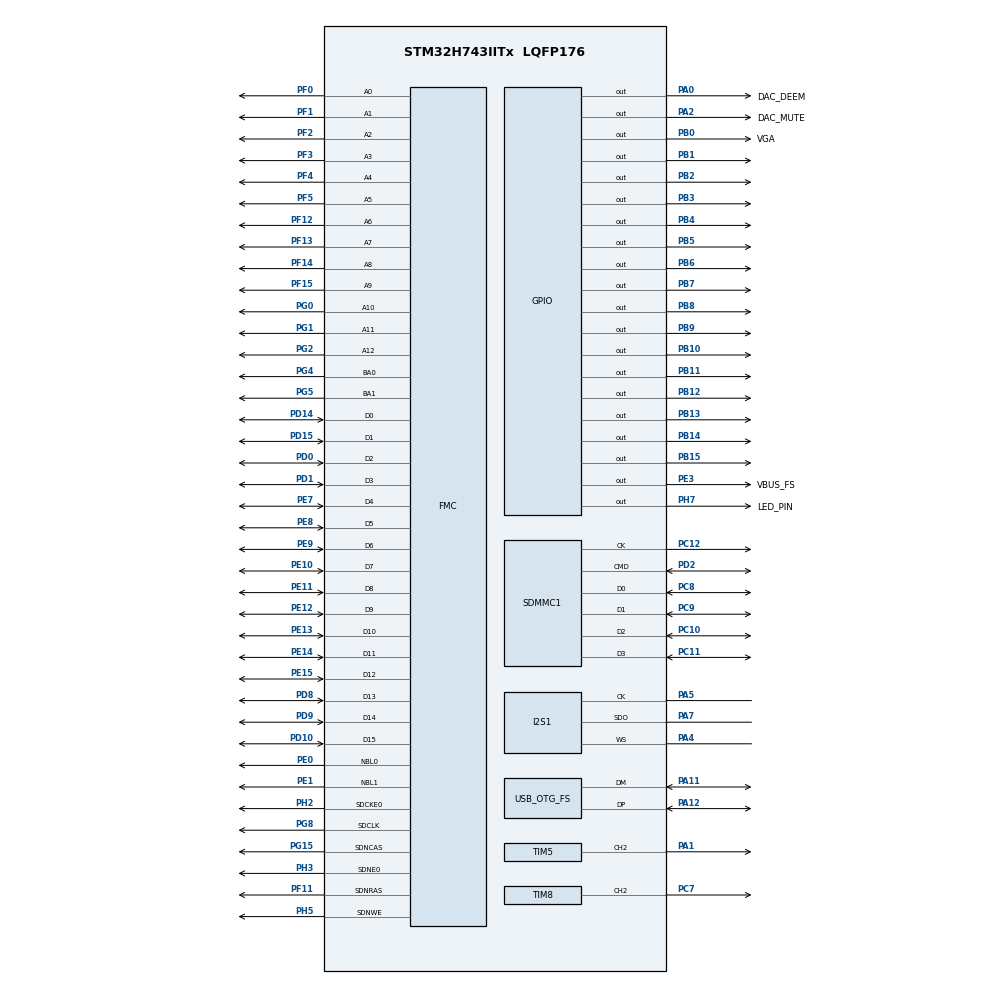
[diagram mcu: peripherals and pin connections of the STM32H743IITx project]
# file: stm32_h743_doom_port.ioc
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CORTEX_M7.AccessPermission_S-Cortex_Memory_Protection_Unit_Region1_Settings_S=MPU_REGION_PRIV_RO
CORTEX_M7.AccessPermission_S-Cortex_Memory_Protection_Unit_Region2_Settings_S=MPU_REGION_FULL_ACCESS
CORTEX_M7.AccessPermission_S-Cortex_Memory_Protection_Unit_Region3_Settings_S=MPU_REGION_FULL_ACCESS
CORTEX_M7.BaseAddress_S-Cortex_Memory_Protection_Unit_Region1_Settings_S=0x08000000
CORTEX_M7.BaseAddress_S-Cortex_Memory_Protection_Unit_Region2_Settings_S=0x38000000
CORTEX_M7.BaseAddress_S-Cortex_Memory_Protection_Unit_Region3_Settings_S=0xC0000000
CORTEX_M7.CPU_DCache=Disabled
CORTEX_M7.CPU_ICache=Enabled
CORTEX_M7.DisableExec_S-Cortex_Memory_Protection_Unit_Region2_Settings_S=MPU_INSTRUCTION_ACCESS_DISABLE
CORTEX_M7.DisableExec_S-Cortex_Memory_Protection_Unit_Region3_Settings_S=MPU_INSTRUCTION_ACCESS_DISABLE
CORTEX_M7.Enable_S-Cortex_Memory_Protection_Unit_Region1_Settings_S=MPU_REGION_ENABLE
CORTEX_M7.Enable_S-Cortex_Memory_Protection_Unit_Region2_Settings_S=MPU_REGION_ENABLE
CORTEX_M7.Enable_S-Cortex_Memory_Protection_Unit_Region3_Settings_S=MPU_REGION_ENABLE
CORTEX_M7.IsBufferable_S-Cortex_Memory_Protection_Unit_Region3_Settings_S=MPU_ACCESS_BUFFERABLE
CORTEX_M7.IsCacheable_S-Cortex_Memory_Protection_Unit_Region1_Settings_S=MPU_ACCESS_CACHEABLE
CORTEX_M7.IsCacheable_S-Cortex_Memory_Protection_Unit_Region3_Settings_S=MPU_ACCESS_CACHEABLE
CORTEX_M7.MPU_Control=__NULL
CORTEX_M7.Number_S-Cortex_Memory_Protection_Unit_Region2_Settings_S=MPU_REGION_NUMBER2
CORTEX_M7.Number_S-Cortex_Memory_Protection_Unit_Region3_Settings_S=MPU_REGION_NUMBER3
CORTEX_M7.Number_S-Cortex_Memory_Protection_Unit_Region4_Settings_S=MPU_REGION_NUMBER4
CORTEX_M7.Size_S-Cortex_Memory_Protection_Unit_Region1_Settings_S=MPU_REGION_SIZE_2MB
CORTEX_M7.Size_S-Cortex_Memory_Protection_Unit_Region2_Settings_S=MPU_REGION_SIZE_16MB
CORTEX_M7.Size_S-Cortex_Memory_Protection_Unit_Region3_Settings_S=MPU_REGION_SIZE_32MB
CORTEX_M7.SubRegionDisable_S-Cortex_Memory_Protection_Unit_Region2_Settings_S=0xEE
CORTEX_M7.TypeExtField_S-Cortex_Memory_Protection_Unit_Region2_Settings_S=MPU_TEX_LEVEL1
CORTEX_M7.TypeExtField_S-Cortex_Memory_Protection_Unit_Region3_Settings_S=MPU_TEX_LEVEL1
CORTEX_M7.default_mode_Activation=1
Dma.MEMTOMEM.1.Direction=DMA_MEMORY_TO_MEMORY
Dma.MEMTOMEM.1.EventEnable=DISABLE
Dma.MEMTOMEM.1.FIFOMode=DMA_FIFOMODE_ENABLE
Dma.MEMTOMEM.1.FIFOThreshold=DMA_FIFO_THRESHOLD_HALFFULL
Dma.MEMTOMEM.1.Instance=DMA1_Stream0
Dma.MEMTOMEM.1.MemBurst=DMA_MBURST_SINGLE
Dma.MEMTOMEM.1.MemDataAlignment=DMA_MDATAALIGN_WORD
Dma.MEMTOMEM.1.MemInc=DMA_MINC_ENABLE
Dma.MEMTOMEM.1.Mode=DMA_NORMAL
Dma.MEMTOMEM.1.PeriphBurst=DMA_PBURST_SINGLE
Dma.MEMTOMEM.1.PeriphDataAlignment=DMA_PDATAALIGN_WORD
Dma.MEMTOMEM.1.PeriphInc=DMA_PINC_ENABLE
Dma.MEMTOMEM.1.Polarity=HAL_DMAMUX_REQ_GEN_RISING
Dma.MEMTOMEM.1.Priority=DMA_PRIORITY_HIGH
Dma.MEMTOMEM.1.RequestNumber=1
Dma.MEMTOMEM.1.SignalID=NONE
Dma.MEMTOMEM.1.SyncEnable=DISABLE
Dma.MEMTOMEM.1.SyncPolarity=HAL_DMAMUX_SYNC_NO_EVENT
Dma.MEMTOMEM.1.SyncRequestNumber=1
Dma.MEMTOMEM.1.SyncSignalID=NONE
Dma.MEMTOMEM.3.Direction=DMA_MEMORY_TO_MEMORY
Dma.MEMTOMEM.3.EventEnable=DISABLE
Dma.MEMTOMEM.3.FIFOMode=DMA_FIFOMODE_ENABLE
Dma.MEMTOMEM.3.FIFOThreshold=DMA_FIFO_THRESHOLD_HALFFULL
Dma.MEMTOMEM.3.Instance=DMA1_Stream1
Dma.MEMTOMEM.3.MemBurst=DMA_MBURST_SINGLE
Dma.MEMTOMEM.3.MemDataAlignment=DMA_MDATAALIGN_WORD
Dma.MEMTOMEM.3.MemInc=DMA_MINC_ENABLE
Dma.MEMTOMEM.3.Mode=DMA_NORMAL
Dma.MEMTOMEM.3.PeriphBurst=DMA_PBURST_SINGLE
Dma.MEMTOMEM.3.PeriphDataAlignment=DMA_PDATAALIGN_WORD
Dma.MEMTOMEM.3.PeriphInc=DMA_PINC_DISABLE
Dma.MEMTOMEM.3.Polarity=HAL_DMAMUX_REQ_GEN_RISING
Dma.MEMTOMEM.3.Priority=DMA_PRIORITY_LOW
Dma.MEMTOMEM.3.RequestNumber=1
Dma.MEMTOMEM.3.SignalID=NONE
Dma.MEMTOMEM.3.SyncEnable=DISABLE
Dma.MEMTOMEM.3.SyncPolarity=HAL_DMAMUX_SYNC_NO_EVENT
Dma.MEMTOMEM.3.SyncRequestNumber=1
Dma.MEMTOMEM.3.SyncSignalID=NONE
Dma.Request0=TIM1_UP
Dma.Request1=MEMTOMEM
Dma.Request2=SPI1_TX
Dma.Request3=MEMTOMEM
Dma.SPI1_TX.2.Direction=DMA_MEMORY_TO_PERIPH
Dma.SPI1_TX.2.EventEnable=DISABLE
Dma.SPI1_TX.2.FIFOMode=DMA_FIFOMODE_ENABLE
Dma.SPI1_TX.2.FIFOThreshold=DMA_FIFO_THRESHOLD_FULL
Dma.SPI1_TX.2.Instance=DMA1_Stream2
Dma.SPI1_TX.2.MemBurst=DMA_MBURST_SINGLE
Dma.SPI1_TX.2.MemDataAlignment=DMA_MDATAALIGN_HALFWORD
Dma.SPI1_TX.2.MemInc=DMA_MINC_ENABLE
Dma.SPI1_TX.2.Mode=DMA_CIRCULAR
Dma.SPI1_TX.2.PeriphBurst=DMA_PBURST_SINGLE
Dma.SPI1_TX.2.PeriphDataAlignment=DMA_PDATAALIGN_HALFWORD
Dma.SPI1_TX.2.PeriphInc=DMA_PINC_DISABLE
Dma.SPI1_TX.2.Polarity=HAL_DMAMUX_REQ_GEN_RISING
Dma.SPI1_TX.2.Priority=DMA_PRIORITY_MEDIUM
Dma.SPI1_TX.2.RequestNumber=1
Dma.SPI1_TX.2.SignalID=NONE
Dma.SPI1_TX.2.SyncEnable=DISABLE
Dma.SPI1_TX.2.SyncPolarity=HAL_DMAMUX_SYNC_NO_EVENT
Dma.SPI1_TX.2.SyncRequestNumber=1
Dma.SPI1_TX.2.SyncSignalID=NONE
Dma.TIM1_UP.0.Direction=DMA_MEMORY_TO_PERIPH
Dma.TIM1_UP.0.EventEnable=DISABLE
Dma.TIM1_UP.0.FIFOMode=DMA_FIFOMODE_ENABLE
Dma.TIM1_UP.0.FIFOThreshold=DMA_FIFO_THRESHOLD_HALFFULL
Dma.TIM1_UP.0.Instance=DMA2_Stream0
Dma.TIM1_UP.0.MemBurst=DMA_MBURST_SINGLE
Dma.TIM1_UP.0.MemDataAlignment=DMA_MDATAALIGN_HALFWORD
Dma.TIM1_UP.0.MemInc=DMA_MINC_ENABLE
Dma.TIM1_UP.0.Mode=DMA_CIRCULAR
Dma.TIM1_UP.0.PeriphBurst=DMA_PBURST_SINGLE
Dma.TIM1_UP.0.PeriphDataAlignment=DMA_PDATAALIGN_HALFWORD
Dma.TIM1_UP.0.PeriphInc=DMA_PINC_DISABLE
Dma.TIM1_UP.0.Polarity=HAL_DMAMUX_REQ_GEN_RISING
Dma.TIM1_UP.0.Priority=DMA_PRIORITY_VERY_HIGH
Dma.TIM1_UP.0.RequestNumber=1
Dma.TIM1_UP.0.SignalID=NONE
Dma.TIM1_UP.0.SyncEnable=DISABLE
Dma.TIM1_UP.0.SyncPolarity=HAL_DMAMUX_SYNC_NO_EVENT
Dma.TIM1_UP.0.SyncRequestNumber=1
Dma.TIM1_UP.0.SyncSignalID=NONE
FATFS.USE_DMA_CODE_SD=1
FATFS._FS_MINIMIZE=0
FMC.BankMapConfig=FMC_SWAPBMAP_DISABLE
FMC.CASLatency1=FMC_SDRAM_CAS_LATENCY_2
FMC.ColumnBitsNumber1=FMC_SDRAM_COLUMN_BITS_NUM_9
FMC.ExitSelfRefreshDelay1=8
FMC.LoadToActiveDelay1=2
FMC.RCDDelay1=2
FMC.RPDelay1=2
FMC.ReadBurst1=FMC_SDRAM_RBURST_ENABLE
FMC.ReadPipeDelay1=FMC_SDRAM_RPIPE_DELAY_1
FMC.ReadPipeDelay2=FMC_SDRAM_RPIPE_DELAY_1
FMC.RowCycleDelay1=7
FMC.SDClockPeriod1=FMC_SDRAM_CLOCK_PERIOD_2
FMC.SelfRefreshTime1=5
FMC.WriteRecoveryTime1=3
I2S1.AudioFreq=I2S_AUDIOFREQ_44K
I2S1.CPOL=I2S_CPOL_LOW
I2S1.DataFormat=I2S_DATAFORMAT_16B
I2S1.ErrorAudioFreq=-1.35 %
I2S1.Instance=SPI$Index
I2S1.RealAudioFreq=43.402 KHz
I2S1.Standard=I2S_STANDARD_PHILIPS
Mcu.Family=STM32H7
Mcu.Name=STM32H743IITx
Mcu.Package=LQFP176
NVIC.OTG_FS_IRQn=true\:1\:0\:true\:false\:true\:false\:true\:true
NVIC.PriorityGroup=NVIC_PRIORITYGROUP_4
NVIC.SDMMC1_IRQn=true\:1\:0\:true\:false\:true\:true\:true\:true
NVIC.TIM2_IRQn=true\:3\:0\:true\:false\:true\:true\:true\:true
NVIC.TIM8_CC_IRQn=true\:0\:0\:true\:false\:true\:true\:true\:true
PA0.GPIO_Label=DAC_DEEM
PA0.GPIO_Speed=GPIO_SPEED_FREQ_HIGH
PA0.Signal=GPIO_Output
PA1.GPIO_Speed=GPIO_SPEED_FREQ_HIGH
PA1.Signal=S_TIM5_CH2
PA11.Mode=Host_Only
PA11.Signal=USB_OTG_FS_DM
PA12.Mode=Host_Only
PA12.Signal=USB_OTG_FS_DP
PA13\ (JTMS/SWDIO).Mode=Serial_Wire
PA13\ (JTMS/SWDIO).Signal=DEBUG_JTMS-SWDIO
PA14\ (JTCK/SWCLK).Mode=Serial_Wire
PA14\ (JTCK/SWCLK).Signal=DEBUG_JTCK-SWCLK
PA2.GPIO_Label=DAC_MUTE
PA2.GPIO_Speed=GPIO_SPEED_FREQ_HIGH
PA2.Signal=GPIO_Output
PA4.Mode=Half_Duplex_Master_Tx
PA4.Signal=I2S1_WS
PA5.Mode=Half_Duplex_Master_Tx
PA5.Signal=I2S1_CK
PA7.Mode=Half_Duplex_Master_Tx
PA7.Signal=I2S1_SDO
PB0.GPIO_Label=VGA
PB0.GPIO_Speed=GPIO_SPEED_FREQ_HIGH
PB0.Signal=GPIO_Output
PB1.GPIO_Speed=GPIO_SPEED_FREQ_HIGH
PB1.Signal=GPIO_Output
PB10.GPIO_Speed=GPIO_SPEED_FREQ_HIGH
PB10.Signal=GPIO_Output
PB11.GPIO_Speed=GPIO_SPEED_FREQ_HIGH
PB11.Signal=GPIO_Output
PB12.GPIO_Speed=GPIO_SPEED_FREQ_HIGH
PB12.Signal=GPIO_Output
PB13.GPIO_Speed=GPIO_SPEED_FREQ_HIGH
PB13.Signal=GPIO_Output
PB14.GPIO_Speed=GPIO_SPEED_FREQ_HIGH
PB14.Signal=GPIO_Output
PB15.GPIO_Speed=GPIO_SPEED_FREQ_HIGH
PB15.Signal=GPIO_Output
PB2.GPIO_Speed=GPIO_SPEED_FREQ_HIGH
PB2.Signal=GPIO_Output
PB3\ (JTDO/TRACESWO).GPIO_Speed=GPIO_SPEED_FREQ_HIGH
PB3\ (JTDO/TRACESWO).Signal=GPIO_Output
PB4\ (NJTRST).GPIO_Speed=GPIO_SPEED_FREQ_HIGH
PB4\ (NJTRST).Signal=GPIO_Output
PB5.GPIO_Speed=GPIO_SPEED_FREQ_HIGH
PB5.Signal=GPIO_Output
PB6.GPIO_Speed=GPIO_SPEED_FREQ_HIGH
PB6.Signal=GPIO_Output
PB7.GPIO_Speed=GPIO_SPEED_FREQ_HIGH
PB7.Signal=GPIO_Output
PB8.GPIO_Speed=GPIO_SPEED_FREQ_HIGH
PB8.Signal=GPIO_Output
PB9.GPIO_Speed=GPIO_SPEED_FREQ_HIGH
PB9.Signal=GPIO_Output
PC10.Mode=SD_4_bits_Wide_bus
PC10.Signal=SDMMC1_D2
PC11.Mode=SD_4_bits_Wide_bus
PC11.Signal=SDMMC1_D3
PC12.Mode=SD_4_bits_Wide_bus
PC12.Signal=SDMMC1_CK
PC7.GPIO_Speed=GPIO_SPEED_FREQ_HIGH
PC7.Signal=S_TIM8_CH2
PC8.Mode=SD_4_bits_Wide_bus
PC8.Signal=SDMMC1_D0
PC9.Mode=SD_4_bits_Wide_bus
PC9.Signal=SDMMC1_D1
PD0.Signal=FMC_D2_DA2
PD1.Signal=FMC_D3_DA3
PD10.Signal=FMC_D15_DA15
PD14.Signal=FMC_D0_DA0
PD15.Signal=FMC_D1_DA1
PD2.Mode=SD_4_bits_Wide_bus
PD2.Signal=SDMMC1_CMD
PD8.Signal=FMC_D13_DA13
PD9.Signal=FMC_D14_DA14
PE0.Signal=FMC_NBL0
PE1.Signal=FMC_NBL1
PE10.Signal=FMC_D7_DA7
PE11.Signal=FMC_D8_DA8
PE12.Signal=FMC_D9_DA9
PE13.Signal=FMC_D10_DA10
PE14.Signal=FMC_D11_DA11
PE15.Signal=FMC_D12_DA12
PE3.GPIO_Label=VBUS_FS
PE3.Signal=GPIO_Output
PE7.Signal=FMC_D4_DA4
PE8.Signal=FMC_D5_DA5
PE9.Signal=FMC_D6_DA6
PF0.Signal=FMC_A0
PF1.Signal=FMC_A1
PF11.Signal=FMC_SDNRAS
PF12.Signal=FMC_A6
PF13.Signal=FMC_A7
PF14.Signal=FMC_A8
PF15.Signal=FMC_A9
PF2.Signal=FMC_A2
PF3.Signal=FMC_A3
PF4.Signal=FMC_A4
PF5.Signal=FMC_A5
PG0.Signal=FMC_A10
PG1.Signal=FMC_A11
PG15.Signal=FMC_SDNCAS
PG2.Signal=FMC_A12
PG4.Signal=FMC_A14_BA0
PG5.Signal=FMC_A15_BA1
PG8.Signal=FMC_SDCLK
PH0-OSC_IN\ (PH0).Mode=HSE-External-Oscillator
PH0-OSC_IN\ (PH0).Signal=RCC_OSC_IN
PH1-OSC_OUT\ (PH1).Mode=HSE-External-Oscillator
PH1-OSC_OUT\ (PH1).Signal=RCC_OSC_OUT
PH2.Mode=SdramChipSelect1_1
PH2.Signal=FMC_SDCKE0
PH3.Mode=SdramChipSelect1_1
PH3.Signal=FMC_SDNE0
PH5.Signal=FMC_SDNWE
PH7.GPIO_Label=LED_PIN
PH7.GPIO_ModeDefaultOutputPP=GPIO_MODE_OUTPUT_PP
PH7.PinState=GPIO_PIN_SET
PH7.Signal=GPIO_Output
ProjectManager.HeapSize=0x400
ProjectManager.StackSize=0x800
ProjectManager.TargetToolchain=STM32CubeIDE
RCC.ADCFreq_Value=50000000
RCC.APB1Freq_Value=113125000
RCC.APB2Freq_Value=113125000
RCC.APB3Freq_Value=113125000
RCC.APB4Freq_Value=113125000
RCC.CortexFreq_Value=452500000
RCC.D1PPRE=RCC_APB3_DIV2
RCC.D2PPRE1=RCC_APB1_DIV2
RCC.D2PPRE2=RCC_APB2_DIV2
RCC.D3PPRE=RCC_APB4_DIV2
RCC.DIVM1=5
RCC.DIVM2=25
RCC.DIVM3=25
RCC.DIVN1=181
RCC.DIVN2=200
RCC.DIVN3=150
RCC.DIVP2=4
RCC.DIVP3=3
RCC.DIVQ3=3
RCC.DIVR2=1
RCC.FMCCLockSelection=RCC_FMCCLKSOURCE_PLL2
RCC.HCLKFreq_Value=226250000
RCC.HPRE=RCC_HCLK_DIV2
RCC.PLLSourceVirtual=RCC_PLLSOURCE_HSE
RCC.SDMMC1CLockSelection=RCC_SDMMCCLKSOURCE_PLL2
RCC.SPI123CLockSelection=RCC_SPI123CLKSOURCE_PLL2
RCC.SYSCLKFreq_VALUE=452500000
RCC.SYSCLKSource=RCC_SYSCLKSOURCE_PLLCLK
RCC.USBCLockSelection=RCC_USBCLKSOURCE_PLL3
RCC.USBFreq_Value=50000000
SDMMC1.ClockDiv=4
SH.FMC_A0.0=FMC_A0,13b-sda1
SH.FMC_A1.0=FMC_A1,13b-sda1
SH.FMC_A10.0=FMC_A10,13b-sda1
SH.FMC_A11.0=FMC_A11,13b-sda1
SH.FMC_A12.0=FMC_A12,13b-sda1
SH.FMC_A14_BA0.0=FMC_BA0,FourSdramBanks1
SH.FMC_A15_BA1.0=FMC_BA1,FourSdramBanks1
SH.FMC_A2.0=FMC_A2,13b-sda1
SH.FMC_A3.0=FMC_A3,13b-sda1
SH.FMC_A4.0=FMC_A4,13b-sda1
SH.FMC_A5.0=FMC_A5,13b-sda1
SH.FMC_A6.0=FMC_A6,13b-sda1
SH.FMC_A7.0=FMC_A7,13b-sda1
SH.FMC_A8.0=FMC_A8,13b-sda1
SH.FMC_A9.0=FMC_A9,13b-sda1
SH.FMC_D0_DA0.0=FMC_D0,sd-16b-d1
SH.FMC_D10_DA10.0=FMC_D10,sd-16b-d1
SH.FMC_D11_DA11.0=FMC_D11,sd-16b-d1
SH.FMC_D12_DA12.0=FMC_D12,sd-16b-d1
SH.FMC_D13_DA13.0=FMC_D13,sd-16b-d1
SH.FMC_D14_DA14.0=FMC_D14,sd-16b-d1
SH.FMC_D15_DA15.0=FMC_D15,sd-16b-d1
SH.FMC_D1_DA1.0=FMC_D1,sd-16b-d1
SH.FMC_D2_DA2.0=FMC_D2,sd-16b-d1
SH.FMC_D3_DA3.0=FMC_D3,sd-16b-d1
SH.FMC_D4_DA4.0=FMC_D4,sd-16b-d1
SH.FMC_D5_DA5.0=FMC_D5,sd-16b-d1
SH.FMC_D6_DA6.0=FMC_D6,sd-16b-d1
SH.FMC_D7_DA7.0=FMC_D7,sd-16b-d1
SH.FMC_D8_DA8.0=FMC_D8,sd-16b-d1
SH.FMC_D9_DA9.0=FMC_D9,sd-16b-d1
SH.FMC_NBL0.0=FMC_NBL0,Sd2ByteEnable1
SH.FMC_NBL1.0=FMC_NBL1,Sd2ByteEnable1
SH.FMC_SDCLK.0=FMC_SDCLK,13b-sda1
SH.FMC_SDNCAS.0=FMC_SDNCAS,13b-sda1
SH.FMC_SDNRAS.0=FMC_SDNRAS,13b-sda1
SH.FMC_SDNWE.0=FMC_SDNWE,13b-sda1
SH.S_TIM5_CH2.0=TIM5_CH2,PWM Generation2 CH2
SH.S_TIM8_CH2.0=TIM8_CH2,PWM Generation2 CH2
TIM1.Period=16
TIM1.TIM_MasterOutputTrigger=TIM_TRGO_UPDATE
TIM1.TIM_MasterOutputTrigger2=TIM_TRGO2_UPDATE
TIM2.Period=4999
TIM2.Prescaler=225
TIM5.Channel-PWM\ Generation2\ CH2=TIM_CHANNEL_2
TIM5.Period=523
TIM5.Prescaler=0
TIM5.Pulse-PWM\ Generation2\ CH2=522
TIM5.TIM_MasterOutputTrigger=TIM_TRGO_UPDATE
TIM8.Channel-Output\ Compare1\ No\ Output=TIM_CHANNEL_1
TIM8.Channel-PWM\ Generation2\ CH2=TIM_CHANNEL_2
TIM8.OCMode_PWM-PWM\ Generation2\ CH2=TIM_OCMODE_PWM1
TIM8.OCPolarity_2=TIM_OCPOLARITY_HIGH
TIM8.Period=399
TIM8.Prescaler=0
TIM8.Pulse-Output\ Compare1\ No\ Output=343
TIM8.Pulse-PWM\ Generation2\ CH2=352
TIM8.TIM_MasterOutputTrigger=TIM_TRGO_UPDATE
TIM8.TIM_MasterOutputTrigger2=TIM_TRGO2_UPDATE
USB_HOST.BSP.number=1
USB_HOST.USBH_HandleTypeDef-HID_FS=hUsbHostFS
USB_HOST.VirtualModeFS=Hid
USB_HOST0.BSP.STBoard=false
USB_HOST0.BSP.api=Unknown
USB_HOST0.BSP.condition=SW_VBUS_DRIVE_HID_FS \= false
USB_HOST0.BSP.instance=PE3
USB_HOST0.BSP.ip=GPIO
USB_HOST0.BSP.mode=Output
USB_HOST0.BSP.name=Drive_VBUS_FS
USB_HOST0.BSP.solution=PE3
USB_OTG_FS.VirtualMode=Host_Only
USB_OTG_FS.phy_itface=HCD_PHY_EMBEDDED
VP_FATFS_VS_SDIO.Mode=SDIO
VP_MEMORYMAP_VS_MEMORYMAP.Mode=CurAppReg
VP_TIM1_VS_ClockSourceINT.Mode=Internal
VP_TIM2_VS_ClockSourceINT.Mode=Internal
VP_TIM5_VS_ClockSourceITR.Mode=TriggerSource_ITR1
VP_TIM5_VS_ControllerModeClock.Mode=Clock Mode
VP_TIM8_VS_ClockSourceITR.Mode=TriggerSource_ITR0
VP_TIM8_VS_ControllerModeClock.Mode=Clock Mode
VP_TIM8_VS_no_output1.Mode=Output Compare1 No Output
VP_USB_HOST_VS_USB_HOST_HID_FS.Mode=HID_FS
board=custom

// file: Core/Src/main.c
/* USER CODE BEGIN Header */
/**
 ******************************************************************************
 * @file           : main.c
 * @brief          : Main program body
 ******************************************************************************
 * @attention
 *
 * Copyright (c) 2025 STMicroelectronics.
 * All rights reserved.
 *
 * This software is licensed under terms that can be found in the LICENSE file
 * in the root directory of this software component.
 * If no LICENSE file comes with this software, it is provided AS-IS.
 *
 ******************************************************************************
 */
/* USER CODE END Header */
#include "main.h"
#include "fatfs.h"
#include "usb_host.h"

/* USER CODE BEGIN Includes */
#include "vga.h"
#include "rgb_disp.h"
#include "string.h"
#include "usbh_hid.h"
#include "i2s.h"

/* USER CODE END Includes */

/* USER CODE BEGIN PD */
extern void D_DoomMain(void);
/* USER CODE END PD */

/* USER CODE BEGIN PM */
#define SDRAM_BEGINNING 0xC0000000

/* USER CODE END PM */

I2S_HandleTypeDef hi2s1;
DMA_HandleTypeDef hdma_spi1_tx;

SD_HandleTypeDef hsd1;

TIM_HandleTypeDef htim1;
TIM_HandleTypeDef htim2;
TIM_HandleTypeDef htim5;
TIM_HandleTypeDef htim8;
DMA_HandleTypeDef hdma_tim1_up;

DMA_HandleTypeDef hdma_memtomem_dma1_stream0;
DMA_HandleTypeDef hdma_memtomem_dma1_stream1;
SDRAM_HandleTypeDef hsdram1;

/* USER CODE BEGIN PV */
FATFS FatFs;
volatile uint32_t g_systime_ms = 0;
volatile uint32_t g_systime_ms_delay = 0;
volatile uint16_t *g_vga_feed_buffer;

uint16_t *pix_pointer;
/* USER CODE END PV */

void SystemClock_Config(void);
void PeriphCommonClock_Config(void);
static void MX_GPIO_Init(void);
static void MX_DMA_Init(void);
static void MX_TIM8_Init(void);
static void MX_TIM1_Init(void);
static void MX_I2S1_Init(void);
static void MX_FMC_Init(void);
static void MX_SDMMC1_SD_Init(void);
static void MX_TIM5_Init(void);
static void MX_TIM2_Init(void);
void MX_USB_HOST_Process(void);

/* USER CODE BEGIN PFP */

static void SDIO_SDCard_Mount(void);

/* USER CODE END PFP */

int main(void)
{

  /* Enable the CPU Cache */

  /* Enable I-Cache---------------------------------------------------------*/
  SCB_EnableICache();

  /* MCU Configuration--------------------------------------------------------*/

  /* Reset of all peripherals, Initializes the Flash interface and the Systick. */
  HAL_Init();

  /* Configure the system clock */
  SystemClock_Config();

  /* Configure the peripherals common clocks */
  PeriphCommonClock_Config();

  /* Initialize all configured peripherals */
  MX_GPIO_Init();
  MX_DMA_Init();
  MX_TIM8_Init();
  MX_TIM1_Init();
  MX_I2S1_Init();
  MX_FMC_Init();
  MX_SDMMC1_SD_Init();
  MX_FATFS_Init();
  MX_TIM5_Init();
  MX_USB_HOST_Init();
  MX_TIM2_Init();
  /* USER CODE BEGIN 2 */
  HAL_TIM_Base_Start_IT(&htim2);

  SDIO_SDCard_Mount();
  vga_init(&pix_pointer, &hdma_tim1_up, &htim1, &htim5);

  rgb_init(pix_pointer, (uint16_t **)&g_vga_feed_buffer, &hdma_memtomem_dma1_stream0);
  HAL_TIM_PWM_Start(&htim8, TIM_CHANNEL_2);
  HAL_TIM_OC_Start_IT(&htim8, TIM_CHANNEL_1);
  HAL_TIM_PWM_Start(&htim5, TIM_CHANNEL_2);

  HAL_TIM_Base_Start(&htim1);
  i2s_set_handle(&hi2s1);
  i2s_set_zeroing_dma_handle(&hdma_memtomem_dma1_stream1,DMA1);

  D_DoomMain();

  /* USER CODE END 2 */

  /* Infinite loop */
  while (1)
  {
    MX_USB_HOST_Process();

  }
}

void SystemClock_Config(void)
{
  RCC_OscInitTypeDef RCC_OscInitStruct = {0};
  RCC_ClkInitTypeDef RCC_ClkInitStruct = {0};

  /** Supply configuration update enable
  */
  HAL_PWREx_ConfigSupply(PWR_LDO_SUPPLY);

  /** Configure the main internal regulator output voltage
  */
  __HAL_PWR_VOLTAGESCALING_CONFIG(PWR_REGULATOR_VOLTAGE_SCALE0);

  while(!__HAL_PWR_GET_FLAG(PWR_FLAG_VOSRDY)) {}

  /** Initializes the RCC Oscillators according to the specified parameters
  * in the RCC_OscInitTypeDef structure.
  */
  RCC_OscInitStruct.OscillatorType = RCC_OSCILLATORTYPE_HSE;
  RCC_OscInitStruct.HSEState = RCC_HSE_ON;
  RCC_OscInitStruct.PLL.PLLState = RCC_PLL_ON;
  RCC_OscInitStruct.PLL.PLLSource = RCC_PLLSOURCE_HSE;
  RCC_OscInitStruct.PLL.PLLM = 5;
  RCC_OscInitStruct.PLL.PLLN = 181;
  RCC_OscInitStruct.PLL.PLLP = 2;
  RCC_OscInitStruct.PLL.PLLQ = 2;
  RCC_OscInitStruct.PLL.PLLR = 2;
  RCC_OscInitStruct.PLL.PLLRGE = RCC_PLL1VCIRANGE_2;
  RCC_OscInitStruct.PLL.PLLVCOSEL = RCC_PLL1VCOWIDE;
  RCC_OscInitStruct.PLL.PLLFRACN = 0;
  if (HAL_RCC_OscConfig(&RCC_OscInitStruct) != HAL_OK)
  {
    Error_Handler();
  }

  /** Initializes the CPU, AHB and APB buses clocks
  */
  RCC_ClkInitStruct.ClockType = RCC_CLOCKTYPE_HCLK|RCC_CLOCKTYPE_SYSCLK
                              |RCC_CLOCKTYPE_PCLK1|RCC_CLOCKTYPE_PCLK2
                              |RCC_CLOCKTYPE_D3PCLK1|RCC_CLOCKTYPE_D1PCLK1;
  RCC_ClkInitStruct.SYSCLKSource = RCC_SYSCLKSOURCE_PLLCLK;
  RCC_ClkInitStruct.SYSCLKDivider = RCC_SYSCLK_DIV1;
  RCC_ClkInitStruct.AHBCLKDivider = RCC_HCLK_DIV2;
  RCC_ClkInitStruct.APB3CLKDivider = RCC_APB3_DIV2;
  RCC_ClkInitStruct.APB1CLKDivider = RCC_APB1_DIV2;
  RCC_ClkInitStruct.APB2CLKDivider = RCC_APB2_DIV2;
  RCC_ClkInitStruct.APB4CLKDivider = RCC_APB4_DIV2;

  if (HAL_RCC_ClockConfig(&RCC_ClkInitStruct, FLASH_LATENCY_4) != HAL_OK)
  {
    Error_Handler();
  }
}

void PeriphCommonClock_Config(void)
{
  RCC_PeriphCLKInitTypeDef PeriphClkInitStruct = {0};

  /** Initializes the peripherals clock
  */
  PeriphClkInitStruct.PeriphClockSelection = RCC_PERIPHCLK_FMC|RCC_PERIPHCLK_SDMMC
                              |RCC_PERIPHCLK_SPI1;
  PeriphClkInitStruct.PLL2.PLL2M = 25;
  PeriphClkInitStruct.PLL2.PLL2N = 200;
  PeriphClkInitStruct.PLL2.PLL2P = 4;
  PeriphClkInitStruct.PLL2.PLL2Q = 2;
  PeriphClkInitStruct.PLL2.PLL2R = 1;
  PeriphClkInitStruct.PLL2.PLL2RGE = RCC_PLL2VCIRANGE_0;
  PeriphClkInitStruct.PLL2.PLL2VCOSEL = RCC_PLL2VCOWIDE;
  PeriphClkInitStruct.PLL2.PLL2FRACN = 0;
  PeriphClkInitStruct.FmcClockSelection = RCC_FMCCLKSOURCE_PLL2;
  PeriphClkInitStruct.SdmmcClockSelection = RCC_SDMMCCLKSOURCE_PLL2;
  PeriphClkInitStruct.Spi123ClockSelection = RCC_SPI123CLKSOURCE_PLL2;
  if (HAL_RCCEx_PeriphCLKConfig(&PeriphClkInitStruct) != HAL_OK)
  {
    Error_Handler();
  }
}

static void MX_I2S1_Init(void)
{

  hi2s1.Instance = SPI1;
  hi2s1.Init.Mode = I2S_MODE_MASTER_TX;
  hi2s1.Init.Standard = I2S_STANDARD_PHILIPS;
  hi2s1.Init.DataFormat = I2S_DATAFORMAT_16B;
  hi2s1.Init.MCLKOutput = I2S_MCLKOUTPUT_DISABLE;
  hi2s1.Init.AudioFreq = I2S_AUDIOFREQ_44K;
  hi2s1.Init.CPOL = I2S_CPOL_LOW;
  hi2s1.Init.FirstBit = I2S_FIRSTBIT_MSB;
  hi2s1.Init.WSInversion = I2S_WS_INVERSION_DISABLE;
  hi2s1.Init.Data24BitAlignment = I2S_DATA_24BIT_ALIGNMENT_RIGHT;
  hi2s1.Init.MasterKeepIOState = I2S_MASTER_KEEP_IO_STATE_DISABLE;
  if (HAL_I2S_Init(&hi2s1) != HAL_OK)
  {
    Error_Handler();
  }

}

static void MX_SDMMC1_SD_Init(void)
{

  hsd1.Instance = SDMMC1;
  hsd1.Init.ClockEdge = SDMMC_CLOCK_EDGE_RISING;
  hsd1.Init.ClockPowerSave = SDMMC_CLOCK_POWER_SAVE_DISABLE;
  hsd1.Init.BusWide = SDMMC_BUS_WIDE_4B;
  hsd1.Init.HardwareFlowControl = SDMMC_HARDWARE_FLOW_CONTROL_DISABLE;
  hsd1.Init.ClockDiv = 4;

}

static void MX_TIM1_Init(void)
{

  TIM_ClockConfigTypeDef sClockSourceConfig = {0};
  TIM_MasterConfigTypeDef sMasterConfig = {0};

  htim1.Instance = TIM1;
  htim1.Init.Prescaler = 0;
  htim1.Init.CounterMode = TIM_COUNTERMODE_UP;
  htim1.Init.Period = 16;
  htim1.Init.ClockDivision = TIM_CLOCKDIVISION_DIV1;
  htim1.Init.RepetitionCounter = 0;
  htim1.Init.AutoReloadPreload = TIM_AUTORELOAD_PRELOAD_DISABLE;
  if (HAL_TIM_Base_Init(&htim1) != HAL_OK)
  {
    Error_Handler();
  }
  sClockSourceConfig.ClockSource = TIM_CLOCKSOURCE_INTERNAL;
  if (HAL_TIM_ConfigClockSource(&htim1, &sClockSourceConfig) != HAL_OK)
  {
    Error_Handler();
  }
  sMasterConfig.MasterOutputTrigger = TIM_TRGO_UPDATE;
  sMasterConfig.MasterOutputTrigger2 = TIM_TRGO2_UPDATE;
  sMasterConfig.MasterSlaveMode = TIM_MASTERSLAVEMODE_DISABLE;
  if (HAL_TIMEx_MasterConfigSynchronization(&htim1, &sMasterConfig) != HAL_OK)
  {
    Error_Handler();
  }

}

static void MX_TIM2_Init(void)
{

  TIM_ClockConfigTypeDef sClockSourceConfig = {0};
  TIM_MasterConfigTypeDef sMasterConfig = {0};

  htim2.Instance = TIM2;
  htim2.Init.Prescaler = 225;
  htim2.Init.CounterMode = TIM_COUNTERMODE_UP;
  htim2.Init.Period = 4999;
  htim2.Init.ClockDivision = TIM_CLOCKDIVISION_DIV1;
  htim2.Init.AutoReloadPreload = TIM_AUTORELOAD_PRELOAD_DISABLE;
  if (HAL_TIM_Base_Init(&htim2) != HAL_OK)
  {
    Error_Handler();
  }
  sClockSourceConfig.ClockSource = TIM_CLOCKSOURCE_INTERNAL;
  if (HAL_TIM_ConfigClockSource(&htim2, &sClockSourceConfig) != HAL_OK)
  {
    Error_Handler();
  }
  sMasterConfig.MasterOutputTrigger = TIM_TRGO_RESET;
  sMasterConfig.MasterSlaveMode = TIM_MASTERSLAVEMODE_DISABLE;
  if (HAL_TIMEx_MasterConfigSynchronization(&htim2, &sMasterConfig) != HAL_OK)
  {
    Error_Handler();
  }

}

static void MX_TIM5_Init(void)
{

  TIM_SlaveConfigTypeDef sSlaveConfig = {0};
  TIM_MasterConfigTypeDef sMasterConfig = {0};
  TIM_OC_InitTypeDef sConfigOC = {0};

  htim5.Instance = TIM5;
  htim5.Init.Prescaler = 0;
  htim5.Init.CounterMode = TIM_COUNTERMODE_UP;
  htim5.Init.Period = 523;
  htim5.Init.ClockDivision = TIM_CLOCKDIVISION_DIV1;
  htim5.Init.AutoReloadPreload = TIM_AUTORELOAD_PRELOAD_DISABLE;
  if (HAL_TIM_Base_Init(&htim5) != HAL_OK)
  {
    Error_Handler();
  }
  if (HAL_TIM_PWM_Init(&htim5) != HAL_OK)
  {
    Error_Handler();
  }
  sSlaveConfig.SlaveMode = TIM_SLAVEMODE_EXTERNAL1;
  sSlaveConfig.InputTrigger = TIM_TS_ITR1;
  if (HAL_TIM_SlaveConfigSynchro(&htim5, &sSlaveConfig) != HAL_OK)
  {
    Error_Handler();
  }
  sMasterConfig.MasterOutputTrigger = TIM_TRGO_UPDATE;
  sMasterConfig.MasterSlaveMode = TIM_MASTERSLAVEMODE_DISABLE;
  if (HAL_TIMEx_MasterConfigSynchronization(&htim5, &sMasterConfig) != HAL_OK)
  {
    Error_Handler();
  }
  sConfigOC.OCMode = TIM_OCMODE_PWM1;
  sConfigOC.Pulse = 522;
  sConfigOC.OCPolarity = TIM_OCPOLARITY_HIGH;
  sConfigOC.OCFastMode = TIM_OCFAST_DISABLE;
  if (HAL_TIM_PWM_ConfigChannel(&htim5, &sConfigOC, TIM_CHANNEL_2) != HAL_OK)
  {
    Error_Handler();
  }
  HAL_TIM_MspPostInit(&htim5);

}

static void MX_TIM8_Init(void)
{

  TIM_SlaveConfigTypeDef sSlaveConfig = {0};
  TIM_MasterConfigTypeDef sMasterConfig = {0};
  TIM_OC_InitTypeDef sConfigOC = {0};
  TIM_BreakDeadTimeConfigTypeDef sBreakDeadTimeConfig = {0};

  htim8.Instance = TIM8;
  htim8.Init.Prescaler = 0;
  htim8.Init.CounterMode = TIM_COUNTERMODE_UP;
  htim8.Init.Period = 399;
  htim8.Init.ClockDivision = TIM_CLOCKDIVISION_DIV1;
  htim8.Init.RepetitionCounter = 0;
  htim8.Init.AutoReloadPreload = TIM_AUTORELOAD_PRELOAD_DISABLE;
  if (HAL_TIM_Base_Init(&htim8) != HAL_OK)
  {
    Error_Handler();
  }
  if (HAL_TIM_OC_Init(&htim8) != HAL_OK)
  {
    Error_Handler();
  }
  if (HAL_TIM_PWM_Init(&htim8) != HAL_OK)
  {
    Error_Handler();
  }
  sSlaveConfig.SlaveMode = TIM_SLAVEMODE_EXTERNAL1;
  sSlaveConfig.InputTrigger = TIM_TS_ITR0;
  if (HAL_TIM_SlaveConfigSynchro(&htim8, &sSlaveConfig) != HAL_OK)
  {
    Error_Handler();
  }
  sMasterConfig.MasterOutputTrigger = TIM_TRGO_UPDATE;
  sMasterConfig.MasterOutputTrigger2 = TIM_TRGO2_UPDATE;
  sMasterConfig.MasterSlaveMode = TIM_MASTERSLAVEMODE_DISABLE;
  if (HAL_TIMEx_MasterConfigSynchronization(&htim8, &sMasterConfig) != HAL_OK)
  {
    Error_Handler();
  }
  sConfigOC.OCMode = TIM_OCMODE_TIMING;
  sConfigOC.Pulse = 343;
  sConfigOC.OCPolarity = TIM_OCPOLARITY_HIGH;
  sConfigOC.OCNPolarity = TIM_OCNPOLARITY_HIGH;
  sConfigOC.OCFastMode = TIM_OCFAST_DISABLE;
  sConfigOC.OCIdleState = TIM_OCIDLESTATE_RESET;
  sConfigOC.OCNIdleState = TIM_OCNIDLESTATE_RESET;
  if (HAL_TIM_OC_ConfigChannel(&htim8, &sConfigOC, TIM_CHANNEL_1) != HAL_OK)
  {
    Error_Handler();
  }
  sConfigOC.OCMode = TIM_OCMODE_PWM1;
  sConfigOC.Pulse = 352;
  if (HAL_TIM_PWM_ConfigChannel(&htim8, &sConfigOC, TIM_CHANNEL_2) != HAL_OK)
  {
    Error_Handler();
  }
  sBreakDeadTimeConfig.OffStateRunMode = TIM_OSSR_DISABLE;
  sBreakDeadTimeConfig.OffStateIDLEMode = TIM_OSSI_DISABLE;
  sBreakDeadTimeConfig.LockLevel = TIM_LOCKLEVEL_OFF;
  sBreakDeadTimeConfig.DeadTime = 0;
  sBreakDeadTimeConfig.BreakState = TIM_BREAK_DISABLE;
  sBreakDeadTimeConfig.BreakPolarity = TIM_BREAKPOLARITY_HIGH;
  sBreakDeadTimeConfig.BreakFilter = 0;
  sBreakDeadTimeConfig.Break2State = TIM_BREAK2_DISABLE;
  sBreakDeadTimeConfig.Break2Polarity = TIM_BREAK2POLARITY_HIGH;
  sBreakDeadTimeConfig.Break2Filter = 0;
  sBreakDeadTimeConfig.AutomaticOutput = TIM_AUTOMATICOUTPUT_DISABLE;
  if (HAL_TIMEx_ConfigBreakDeadTime(&htim8, &sBreakDeadTimeConfig) != HAL_OK)
  {
    Error_Handler();
  }
  HAL_TIM_MspPostInit(&htim8);

}

static void MX_DMA_Init(void)
{

  /* DMA controller clock enable */
  __HAL_RCC_DMA2_CLK_ENABLE();
  __HAL_RCC_DMA1_CLK_ENABLE();

  /* Configure DMA request hdma_memtomem_dma1_stream0 on DMA1_Stream0 */
  hdma_memtomem_dma1_stream0.Instance = DMA1_Stream0;
  hdma_memtomem_dma1_stream0.Init.Request = DMA_REQUEST_MEM2MEM;
  hdma_memtomem_dma1_stream0.Init.Direction = DMA_MEMORY_TO_MEMORY;
  hdma_memtomem_dma1_stream0.Init.PeriphInc = DMA_PINC_ENABLE;
  hdma_memtomem_dma1_stream0.Init.MemInc = DMA_MINC_ENABLE;
  hdma_memtomem_dma1_stream0.Init.PeriphDataAlignment = DMA_PDATAALIGN_WORD;
  hdma_memtomem_dma1_stream0.Init.MemDataAlignment = DMA_MDATAALIGN_WORD;
  hdma_memtomem_dma1_stream0.Init.Mode = DMA_NORMAL;
  hdma_memtomem_dma1_stream0.Init.Priority = DMA_PRIORITY_HIGH;
  hdma_memtomem_dma1_stream0.Init.FIFOMode = DMA_FIFOMODE_ENABLE;
  hdma_memtomem_dma1_stream0.Init.FIFOThreshold = DMA_FIFO_THRESHOLD_HALFFULL;
  hdma_memtomem_dma1_stream0.Init.MemBurst = DMA_MBURST_SINGLE;
  hdma_memtomem_dma1_stream0.Init.PeriphBurst = DMA_PBURST_SINGLE;
  if (HAL_DMA_Init(&hdma_memtomem_dma1_stream0) != HAL_OK)
  {
    Error_Handler( );
  }

  /* Configure DMA request hdma_memtomem_dma1_stream1 on DMA1_Stream1 */
  hdma_memtomem_dma1_stream1.Instance = DMA1_Stream1;
  hdma_memtomem_dma1_stream1.Init.Request = DMA_REQUEST_MEM2MEM;
  hdma_memtomem_dma1_stream1.Init.Direction = DMA_MEMORY_TO_MEMORY;
  hdma_memtomem_dma1_stream1.Init.PeriphInc = DMA_PINC_DISABLE;
  hdma_memtomem_dma1_stream1.Init.MemInc = DMA_MINC_ENABLE;
  hdma_memtomem_dma1_stream1.Init.PeriphDataAlignment = DMA_PDATAALIGN_WORD;
  hdma_memtomem_dma1_stream1.Init.MemDataAlignment = DMA_MDATAALIGN_WORD;
  hdma_memtomem_dma1_stream1.Init.Mode = DMA_NORMAL;
  hdma_memtomem_dma1_stream1.Init.Priority = DMA_PRIORITY_LOW;
  hdma_memtomem_dma1_stream1.Init.FIFOMode = DMA_FIFOMODE_ENABLE;
  hdma_memtomem_dma1_stream1.Init.FIFOThreshold = DMA_FIFO_THRESHOLD_HALFFULL;
  hdma_memtomem_dma1_stream1.Init.MemBurst = DMA_MBURST_SINGLE;
  hdma_memtomem_dma1_stream1.Init.PeriphBurst = DMA_PBURST_SINGLE;
  if (HAL_DMA_Init(&hdma_memtomem_dma1_stream1) != HAL_OK)
  {
    Error_Handler( );
  }

}

/* FMC initialization function */
static void MX_FMC_Init(void)
{

  /* USER CODE BEGIN FMC_Init 0 */
#define SDRAM_MODEREG_BURST_LENGTH_1 ((uint16_t)0x0000)
#define SDRAM_MODEREG_BURST_LENGTH_2 ((uint16_t)0x0001)
#define SDRAM_MODEREG_BURST_LENGTH_4 ((uint16_t)0x0002)
#define SDRAM_MODEREG_BURST_LENGTH_8 ((uint16_t)0x0003)
#define SDRAM_MODEREG_BURST_LENGTH_PAGE ((uint16_t)0x0007)
#define SDRAM_MODEREG_BURST_TYPE_SEQUENTIAL ((uint16_t)0x0000)
#define SDRAM_MODEREG_BURST_TYPE_INTERLEAVED ((uint16_t)0x0008)
#define SDRAM_MODEREG_CAS_LATENCY_2 ((uint16_t)0x0020)
#define SDRAM_MODEREG_CAS_LATENCY_3 ((uint16_t)0x0030)
#define SDRAM_MODEREG_OPERATING_MODE_STANDARD ((uint16_t)0x0000)
#define SDRAM_MODEREG_WRITEBURST_MODE_PROGRAMMED ((uint16_t)0x0000)
#define SDRAM_MODEREG_WRITEBURST_MODE_SINGLE ((uint16_t)0x0200)

  /* USER CODE END FMC_Init 0 */

  FMC_SDRAM_TimingTypeDef SdramTiming = {0};

  /** Perform the SDRAM1 memory initialization sequence
  */
  hsdram1.Instance = FMC_SDRAM_DEVICE;
  /* hsdram1.Init */
  hsdram1.Init.SDBank = FMC_SDRAM_BANK1;
  hsdram1.Init.ColumnBitsNumber = FMC_SDRAM_COLUMN_BITS_NUM_9;
  hsdram1.Init.RowBitsNumber = FMC_SDRAM_ROW_BITS_NUM_13;
  hsdram1.Init.MemoryDataWidth = FMC_SDRAM_MEM_BUS_WIDTH_16;
  hsdram1.Init.InternalBankNumber = FMC_SDRAM_INTERN_BANKS_NUM_4;
  hsdram1.Init.CASLatency = FMC_SDRAM_CAS_LATENCY_2;
  hsdram1.Init.WriteProtection = FMC_SDRAM_WRITE_PROTECTION_DISABLE;
  hsdram1.Init.SDClockPeriod = FMC_SDRAM_CLOCK_PERIOD_2;
  hsdram1.Init.ReadBurst = FMC_SDRAM_RBURST_ENABLE;
  hsdram1.Init.ReadPipeDelay = FMC_SDRAM_RPIPE_DELAY_1;
  /* SdramTiming */
  SdramTiming.LoadToActiveDelay = 2;
  SdramTiming.ExitSelfRefreshDelay = 8;
  SdramTiming.SelfRefreshTime = 5;
  SdramTiming.RowCycleDelay = 7;
  SdramTiming.WriteRecoveryTime = 3;
  SdramTiming.RPDelay = 2;
  SdramTiming.RCDDelay = 2;

  if (HAL_SDRAM_Init(&hsdram1, &SdramTiming) != HAL_OK)
  {
    Error_Handler( );
  }

  /* USER CODE BEGIN FMC_Init 2 */
  FMC_SDRAM_CommandTypeDef Command;
  /* Step 1 and Step 2 already done in HAL_SDRAM_Init() */
  /* Step 3: Configure a clock configuration enable command */
  Command.CommandMode = FMC_SDRAM_CMD_CLK_ENABLE;     /* Set MODE bits to "001" */
  Command.CommandTarget = FMC_SDRAM_CMD_TARGET_BANK1; /* configure the Target Bank bits */
  Command.AutoRefreshNumber = 1;
  Command.ModeRegisterDefinition = 0;
  HAL_SDRAM_SendCommand(&hsdram1, &Command, 0xfff);
  HAL_Delay(1); /* Step 4: Insert 100 us minimum delay - Min HAL Delay is 1ms */
  /* Step 5: Configure a PALL (precharge all) command */
  Command.CommandMode = FMC_SDRAM_CMD_PALL; /* Set MODE bits to "010" */
  HAL_SDRAM_SendCommand(&hsdram1, &Command, 0xfff);
  /* Step 6: Configure an Auto Refresh command */
  Command.CommandMode = FMC_SDRAM_CMD_AUTOREFRESH_MODE; /* Set MODE bits to "011" */
  Command.AutoRefreshNumber = 2;
  HAL_SDRAM_SendCommand(&hsdram1, &Command, 0xfff);
  /* Step 7: Program the external memory mode register */
  Command.CommandMode = FMC_SDRAM_CMD_LOAD_MODE; /*set the MODE bits to "100" */
  // Command.ModeRegisterDefinition =  (uint32_t)0 | 0<<3 | 2<<4 | 0<<7 | 1<<9;
  // Command.ModeRegisterDefinition = (uint32_t)0 | 0 << 3 | 2 << 4 | 0 << 7 | 1 << 9 | SDRAM_MODEREG_BURST_LENGTH_8 | SDRAM_MODEREG_BURST_TYPE_INTERLEAVED;
  Command.ModeRegisterDefinition = (uint32_t)SDRAM_MODEREG_WRITEBURST_MODE_SINGLE | SDRAM_MODEREG_CAS_LATENCY_2 |
                                   SDRAM_MODEREG_BURST_LENGTH_2 | SDRAM_MODEREG_BURST_TYPE_INTERLEAVED;

  HAL_SDRAM_SendCommand(&hsdram1, &Command, 0xfff);

  /* Step 8: Set the refresh rate counter - refer to section SDRAM refresh timer register in RM0455 */
  /* Set the device refresh rate
   * COUNT = [(SDRAM self refresh time / number of row) x  SDRAM CLK] – 20
           = [(64ms/8192) * 113MHz] - 20 =~ 863 */
  HAL_SDRAM_ProgramRefreshRate(&hsdram1, 400);
  /* USER CODE END FMC_Init 2 */
}

static void MX_GPIO_Init(void)
{
  GPIO_InitTypeDef GPIO_InitStruct = {0};

  /* GPIO Ports Clock Enable */
  __HAL_RCC_GPIOE_CLK_ENABLE();
  __HAL_RCC_GPIOF_CLK_ENABLE();
  __HAL_RCC_GPIOH_CLK_ENABLE();
  __HAL_RCC_GPIOA_CLK_ENABLE();
  __HAL_RCC_GPIOB_CLK_ENABLE();
  __HAL_RCC_GPIOG_CLK_ENABLE();
  __HAL_RCC_GPIOD_CLK_ENABLE();
  __HAL_RCC_GPIOC_CLK_ENABLE();

  /*Configure GPIO pin Output Level */
  HAL_GPIO_WritePin(VBUS_FS_GPIO_Port, VBUS_FS_Pin, GPIO_PIN_RESET);

  /*Configure GPIO pin Output Level */
  HAL_GPIO_WritePin(GPIOA, DAC_DEEM_Pin|DAC_MUTE_Pin, GPIO_PIN_RESET);

  /*Configure GPIO pin Output Level */
  HAL_GPIO_WritePin(GPIOB, VGA_Pin|GPIO_PIN_1|GPIO_PIN_2|GPIO_PIN_10
                          |GPIO_PIN_11|GPIO_PIN_12|GPIO_PIN_13|GPIO_PIN_14
                          |GPIO_PIN_15|GPIO_PIN_3|GPIO_PIN_4|GPIO_PIN_5
                          |GPIO_PIN_6|GPIO_PIN_7|GPIO_PIN_8|GPIO_PIN_9, GPIO_PIN_RESET);

  /*Configure GPIO pin Output Level */
  HAL_GPIO_WritePin(LED_PIN_GPIO_Port, LED_PIN_Pin, GPIO_PIN_SET);

  /*Configure GPIO pin : VBUS_FS_Pin */
  GPIO_InitStruct.Pin = VBUS_FS_Pin;
  GPIO_InitStruct.Mode = GPIO_MODE_OUTPUT_PP;
  GPIO_InitStruct.Pull = GPIO_NOPULL;
  GPIO_InitStruct.Speed = GPIO_SPEED_FREQ_LOW;
  HAL_GPIO_Init(VBUS_FS_GPIO_Port, &GPIO_InitStruct);

  /*Configure GPIO pins : DAC_DEEM_Pin DAC_MUTE_Pin */
  GPIO_InitStruct.Pin = DAC_DEEM_Pin|DAC_MUTE_Pin;
  GPIO_InitStruct.Mode = GPIO_MODE_OUTPUT_PP;
  GPIO_InitStruct.Pull = GPIO_NOPULL;
  GPIO_InitStruct.Speed = GPIO_SPEED_FREQ_HIGH;
  HAL_GPIO_Init(GPIOA, &GPIO_InitStruct);

  /*Configure GPIO pins : VGA_Pin PB1 PB2 PB10
                           PB11 PB12 PB13 PB14
                           PB15 PB3 PB4 PB5
                           PB6 PB7 PB8 PB9 */
  GPIO_InitStruct.Pin = VGA_Pin|GPIO_PIN_1|GPIO_PIN_2|GPIO_PIN_10
                          |GPIO_PIN_11|GPIO_PIN_12|GPIO_PIN_13|GPIO_PIN_14
                          |GPIO_PIN_15|GPIO_PIN_3|GPIO_PIN_4|GPIO_PIN_5
                          |GPIO_PIN_6|GPIO_PIN_7|GPIO_PIN_8|GPIO_PIN_9;
  GPIO_InitStruct.Mode = GPIO_MODE_OUTPUT_PP;
  GPIO_InitStruct.Pull = GPIO_NOPULL;
  GPIO_InitStruct.Speed = GPIO_SPEED_FREQ_HIGH;
  HAL_GPIO_Init(GPIOB, &GPIO_InitStruct);

  /*Configure GPIO pin : LED_PIN_Pin */
  GPIO_InitStruct.Pin = LED_PIN_Pin;
  GPIO_InitStruct.Mode = GPIO_MODE_OUTPUT_PP;
  GPIO_InitStruct.Pull = GPIO_NOPULL;
  GPIO_InitStruct.Speed = GPIO_SPEED_FREQ_LOW;
  HAL_GPIO_Init(LED_PIN_GPIO_Port, &GPIO_InitStruct);

}

/* USER CODE BEGIN 4 */

static void SDIO_SDCard_Mount(void)
{
  // FATFS FatFs;
  FRESULT FR_Status;

  //------------------[ Mount The SD Card ]--------------------
  FR_Status = f_mount(&FatFs, SDPath, 1);
  if (FR_Status != FR_OK)
  {
    return;
  }
}

void main_sleep_func(void)
{
  //MX_USB_HOST_Process();
}
/* USER CODE END 4 */

void Error_Handler(void)
{
  __disable_irq();
  while (1)
  {
  }
}
